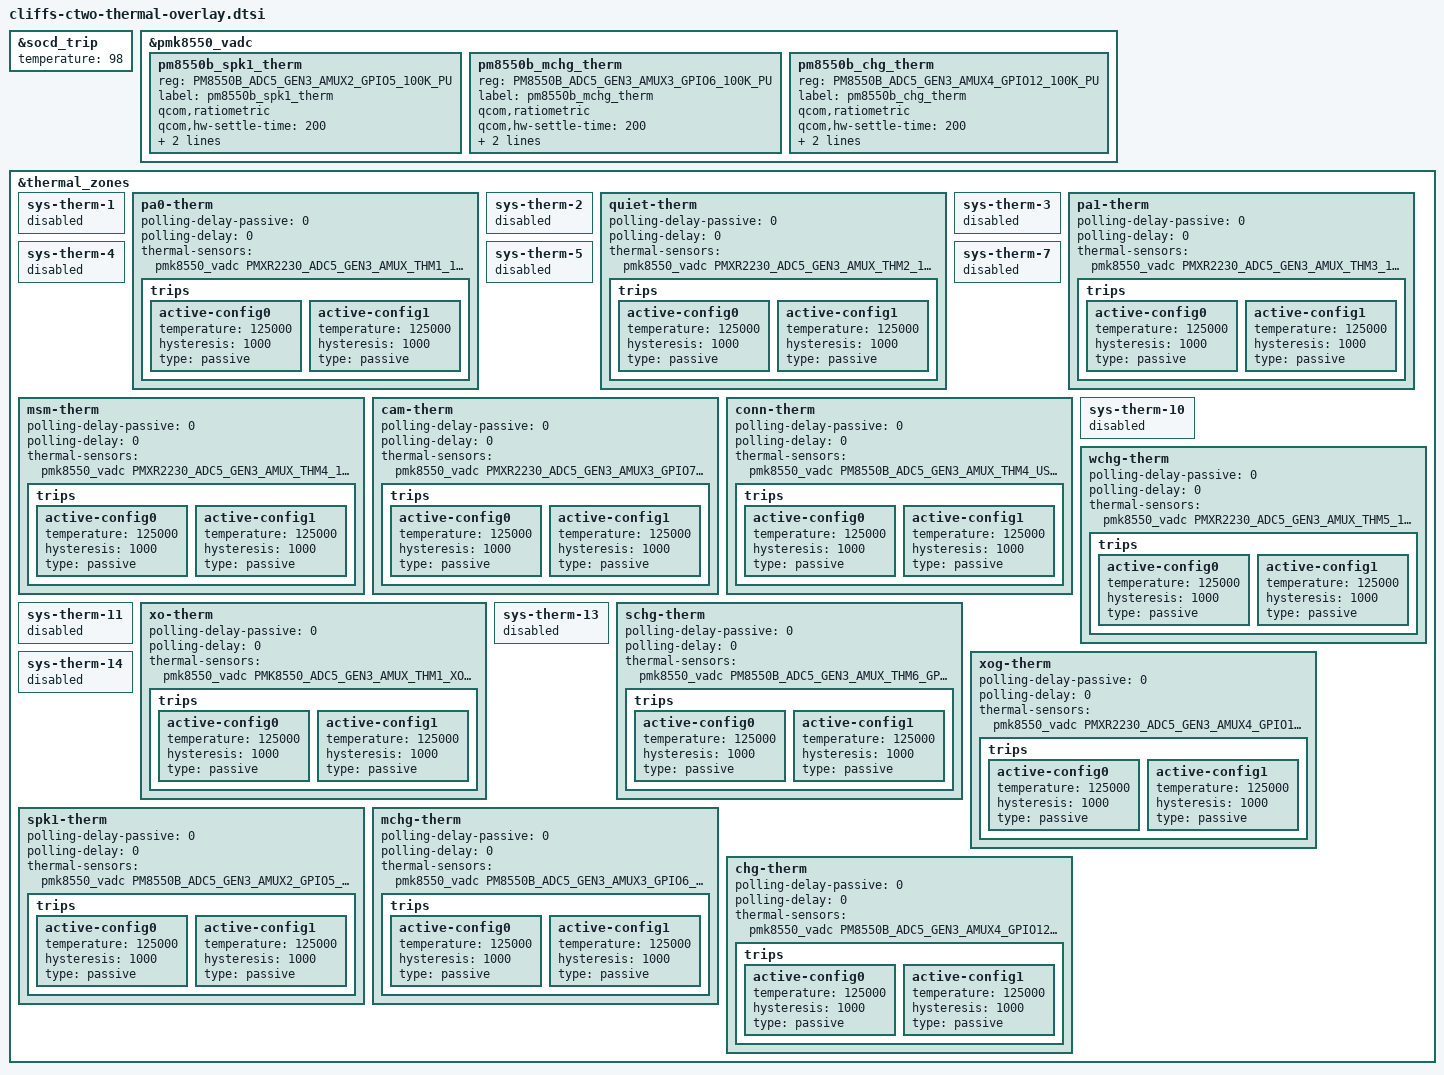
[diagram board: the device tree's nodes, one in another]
#include "moto_therm_sys_temp.dtsi"

&socd_trip {
    temperature = <98>;
};

&pmk8550_vadc {
	pm8550b_spk1_therm {
		reg = <PM8550B_ADC5_GEN3_AMUX2_GPIO5_100K_PU>;
		label = "pm8550b_spk1_therm";
		qcom,ratiometric;
		qcom,hw-settle-time = <200>;
		qcom,pre-scaling = <1 1>;
		qcom,adc-tm-type = <1>;
	};
	pm8550b_mchg_therm {
		reg = <PM8550B_ADC5_GEN3_AMUX3_GPIO6_100K_PU>;
		label = "pm8550b_mchg_therm";
		qcom,ratiometric;
		qcom,hw-settle-time = <200>;
		qcom,pre-scaling = <1 1>;
		qcom,adc-tm-type = <1>;
	};
	pm8550b_chg_therm {
		reg = <PM8550B_ADC5_GEN3_AMUX4_GPIO12_100K_PU>;
		label = "pm8550b_chg_therm";
		qcom,ratiometric;
		qcom,hw-settle-time = <200>;
		qcom,pre-scaling = <1 1>;
		qcom,adc-tm-type = <1>;
	};
};

&thermal_zones {
	sys-therm-1 {
		status = "disabled";
	};
	pa0-therm {
		polling-delay-passive = <0>;
		polling-delay = <0>;
		thermal-sensors = <&pmk8550_vadc PMXR2230_ADC5_GEN3_AMUX_THM1_100K_PU>;
		trips {
			active-config0 {
				temperature = <125000>;
				hysteresis = <1000>;
				type = "passive";
			};

			active-config1 {
				temperature = <125000>;
				hysteresis = <1000>;
				type = "passive";
			};
		};
	};

	sys-therm-2 {
		status = "disabled";
	};
	quiet-therm {
		polling-delay-passive = <0>;
		polling-delay = <0>;
		thermal-sensors = <&pmk8550_vadc PMXR2230_ADC5_GEN3_AMUX_THM2_100K_PU>;
		trips {
			active-config0 {
				temperature = <125000>;
				hysteresis = <1000>;
				type = "passive";
			};

			active-config1 {
				temperature = <125000>;
				hysteresis = <1000>;
				type = "passive";
			};
		};
	};

	sys-therm-3 {
		status = "disabled";
	};
	pa1-therm {
		polling-delay-passive = <0>;
		polling-delay = <0>;
		thermal-sensors = <&pmk8550_vadc PMXR2230_ADC5_GEN3_AMUX_THM3_100K_PU>;
		trips {
			active-config0 {
				temperature = <125000>;
				hysteresis = <1000>;
				type = "passive";
			};

			active-config1 {
				temperature = <125000>;
				hysteresis = <1000>;
				type = "passive";
			};
		};
	};

	sys-therm-4 {
		status = "disabled";
	};
	msm-therm {
		polling-delay-passive = <0>;
		polling-delay = <0>;
		thermal-sensors = <&pmk8550_vadc PMXR2230_ADC5_GEN3_AMUX_THM4_100K_PU>;
		trips {
			active-config0 {
				temperature = <125000>;
				hysteresis = <1000>;
				type = "passive";
			};

			active-config1 {
				temperature = <125000>;
				hysteresis = <1000>;
				type = "passive";
			};
		};
	};

	sys-therm-5 {
		status = "disabled";
	};
	cam-therm {
		polling-delay-passive = <0>;
		polling-delay = <0>;
		thermal-sensors = <&pmk8550_vadc PMXR2230_ADC5_GEN3_AMUX3_GPIO7_100K_PU>;
		trips {
			active-config0 {
				temperature = <125000>;
				hysteresis = <1000>;
				type = "passive";
			};

			active-config1 {
				temperature = <125000>;
				hysteresis = <1000>;
				type = "passive";
			};
		};
	};

	sys-therm-7 {
		status = "disabled";
	};
	conn-therm {
		polling-delay-passive = <0>;
		polling-delay = <0>;
		thermal-sensors = <&pmk8550_vadc PM8550B_ADC5_GEN3_AMUX_THM4_USB_THERM_100K_PU>;
		trips {
			active-config0 {
				temperature = <125000>;
				hysteresis = <1000>;
				type = "passive";
			};

			active-config1 {
				temperature = <125000>;
				hysteresis = <1000>;
				type = "passive";
			};
		};
	};

	sys-therm-10 {
		status = "disabled";
	};
	wchg-therm {
		polling-delay-passive = <0>;
		polling-delay = <0>;
		thermal-sensors = <&pmk8550_vadc PMXR2230_ADC5_GEN3_AMUX_THM5_100K_PU>;
		trips {
			active-config0 {
				temperature = <125000>;
				hysteresis = <1000>;
				type = "passive";
			};

			active-config1 {
				temperature = <125000>;
				hysteresis = <1000>;
				type = "passive";
			};
		};
	};

	sys-therm-11 {
		status = "disabled";
	};
	xo-therm {
		polling-delay-passive = <0>;
		polling-delay = <0>;
		thermal-sensors = <&pmk8550_vadc PMK8550_ADC5_GEN3_AMUX_THM1_XO_THERM_100K_PU>;
		trips {
			active-config0 {
				temperature = <125000>;
				hysteresis = <1000>;
				type = "passive";
			};

			active-config1 {
				temperature = <125000>;
				hysteresis = <1000>;
				type = "passive";
			};
		};
	};

	sys-therm-13 {
		status = "disabled";
	};
	schg-therm {
		polling-delay-passive = <0>;
		polling-delay = <0>;
		thermal-sensors = <&pmk8550_vadc PM8550B_ADC5_GEN3_AMUX_THM6_GPIO10_100K_PU>;
		trips {
			active-config0 {
				temperature = <125000>;
				hysteresis = <1000>;
				type = "passive";
			};

			active-config1 {
				temperature = <125000>;
				hysteresis = <1000>;
				type = "passive";
			};
		};
	};

	sys-therm-14 {
		status = "disabled";
	};
	xog-therm {
		polling-delay-passive = <0>;
		polling-delay = <0>;
		thermal-sensors = <&pmk8550_vadc PMXR2230_ADC5_GEN3_AMUX4_GPIO10_100K_PU>;
		trips {
			active-config0 {
				temperature = <125000>;
				hysteresis = <1000>;
				type = "passive";
			};

			active-config1 {
				temperature = <125000>;
				hysteresis = <1000>;
				type = "passive";
			};
		};
	};

	spk1-therm {
		polling-delay-passive = <0>;
		polling-delay = <0>;
		thermal-sensors = <&pmk8550_vadc PM8550B_ADC5_GEN3_AMUX2_GPIO5_100K_PU>;
		trips {
			active-config0 {
				temperature = <125000>;
				hysteresis = <1000>;
				type = "passive";
			};

			active-config1 {
				temperature = <125000>;
				hysteresis = <1000>;
				type = "passive";
			};
		};
	};

	mchg-therm {
		polling-delay-passive = <0>;
		polling-delay = <0>;
		thermal-sensors = <&pmk8550_vadc PM8550B_ADC5_GEN3_AMUX3_GPIO6_100K_PU>;
		trips {
			active-config0 {
				temperature = <125000>;
				hysteresis = <1000>;
				type = "passive";
			};

			active-config1 {
				temperature = <125000>;
				hysteresis = <1000>;
				type = "passive";
			};
		};
	};

	chg-therm {
		polling-delay-passive = <0>;
		polling-delay = <0>;
		thermal-sensors = <&pmk8550_vadc PM8550B_ADC5_GEN3_AMUX4_GPIO12_100K_PU>;
		trips {
			active-config0 {
				temperature = <125000>;
				hysteresis = <1000>;
				type = "passive";
			};

			active-config1 {
				temperature = <125000>;
				hysteresis = <1000>;
				type = "passive";
			};
		};
	};
};
